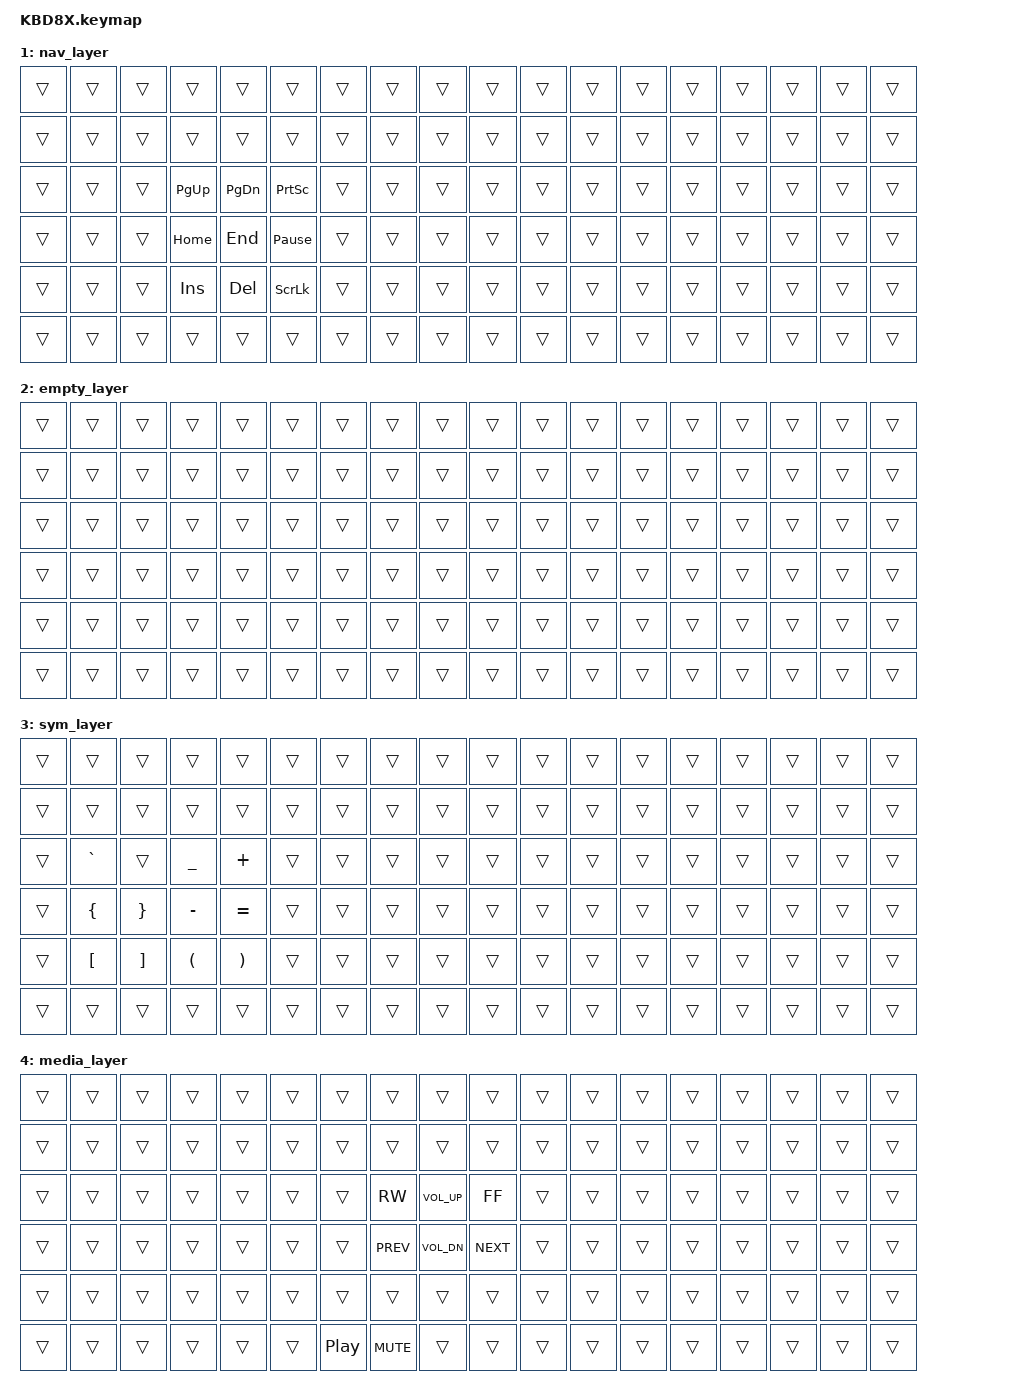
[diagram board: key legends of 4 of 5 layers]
/*
 * Copyright (c) 2020 The ZMK Contributors
 * test
 * SPDX-License-Identifier: MIT
 */

#include <behaviors.dtsi>
#include <dt-bindings/zmk/keys.h>

#define BASE 0
#define NAV 1
#define EMPTY 2
#define SYM 3
#define MEDIA 4

/ {

    keymap {
        compatible = "zmk,keymap";

        base {

// --------- Default QWERTY Layout ---------
// Layer 0 BASE
// --------------------------------------------------------------------------------------------------------------
// | ESC |     | F1  | F2  | F3  | F4  | F5  | F6  | F7  | F8  |     | F9  | F10 | F11 | F12 |PrtSc|Scrll| Pause|
// --------------------------------------------------------------------------------------------------------------
// |  ~  |  1  |  2  |  3  |  4  |  5  |  6  |  7  |  8  |  9  |  0  |  ÷  |  ×  |  -  | Bspc| Ins | Home| PgUp |
// --------------------------------------------------------------------------------------------------------------
// | TAB |  Q  |  W  |  E  |  R  |  T  |  Y  |  U  |  I  |  O  |  P  | N7  | N8  | N9  |  \  | Del | End | PgDn |
// --------------------------------------------------------------------------------------------------------------
// | Fn1 |  A  |  S  |  D  |  F  |  G  |  H  |  J  |  K  |  L  |  ;  | N4  | N5  | N6  |  +  |                  |
// --------------------------------------------------------------------------------------------------------------
// |LSHFT|  Z  |  X  |  C  |  V  |  B  |  N  |  M  |  ,  |  .  |  /  | N1  | N2  | N3  |Enter|     | Up  |      |
// --------------------------------------------------------------------------------------------------------------
// | LCTL| LGUI| LALT| Fn2 | Fn3 | Spc | Bspc|  '  | Fn4 | RALT| RGUI| N0  | N00 | N.  |RCTRL| Left| Down| Right|
// --------------------------------------------------------------------------------------------------------------


            bindings = <
                &kp ESC    &trans    &kp F1    &kp F2     &kp F3     &kp F4     &kp F5    &kp F6   &kp F7     &kp F8              &kp F9        &kp F10          &kp F11       &kp F12      &kp PSCRN  &kp SLCK  &kp PAUSE_BREAK
                &kp TILDE  &kp N1    &kp N2    &kp N3     &kp N4     &kp N5     &kp N6    &kp N7   &kp N8     &kp N9    &kp N0    &kp KP_SLASH  &kp KP_MULTIPLY  &kp KP_MINUS  &kp BSPC     &kp INS    &kp HOME  &kp PG_UP
                &kp TAB    &kp Q     &kp W     &kp E      &kp R      &kp T      &kp Y     &kp U    &kp I      &kp O     &kp P     &kp KP_N7     &kp KP_N8        &kp KP_N9     &kp BSLH     &kp DEL    &kp END   &kp PG_DN
                &kp LBKT   &kp A     &kp S     &kp D      &kp F      &kp G      &kp H     &kp J    &kp K      &kp L     &kp SEMI  &kp KP_N4     &kp KP_N5        &kp KP_N6     &kp KP_PLUS  &trans     &trans    &trans
                &kp LSHFT  &kp Z     &kp X     &kp C      &kp V      &kp B      &kp N     &kp M    &kp COMMA  &kp DOT   &kp FSLH  &kp KP_N1     &kp KP_N2        &kp KP_N3     &kp ENTER    &trans     &kp UP    &trans
                &kp LCTRL  &kp LGUI  &kp LALT  &kp RBKT   &kp PLUS   &kp SPACE  &kp BSPC  &kp SQT  &kp EQUAL  &kp RALT  &kp RGUI  &kp KP_N0     &kp KP_N0        &kp KP_DOT    &kp RCTRL    &kp LEFT   &kp DOWN  &kp RIGHT
            >;
            sensor-bindings = <&inc_dec_kp C_VOL_DN C_VOL_UP>;
        };

        nav_layer {
// Layer 1 FUNC1
// --------------------------------------------------------------------------------------------------------------
// |     |     |     |     |     |     |     |     |     |     |     |     |     |     |     |     |     |      |
// --------------------------------------------------------------------------------------------------------------
// |     |     |     |     |     |     |     |     |     |     |     |     |     |     |     |     |     |      |
// --------------------------------------------------------------------------------------------------------------
// |     |     |     | PgUp| PgDn| Pscr|     |     |     |     |     |     |     |     |     |     |     |      |
// --------------------------------------------------------------------------------------------------------------
// | Fn1 |     |     | Home| End |Pause|     |     |     |     |     |     |     |     |     |     |     |      |
// --------------------------------------------------------------------------------------------------------------
// |     |     |     | Ins | Del | Slck|     |     |     |     |     |     |     |     |     |     |     |      |
// --------------------------------------------------------------------------------------------------------------
// |     |     |     |     |     |     |     |     |     |     |     |     |     |     |     |     |     |      |
// --------------------------------------------------------------------------------------------------------------
            bindings = <
                &trans  &trans     &trans    &trans     &trans     &trans           &trans  &trans  &trans  &trans  &trans  &trans  &trans  &trans  &trans  &trans  &trans  &trans
                &trans  &trans     &trans    &trans     &trans     &trans           &trans  &trans  &trans  &trans  &trans  &trans  &trans  &trans  &trans  &trans  &trans  &trans
                &trans  &trans     &trans    &kp PG_UP  &kp PG_DN  &kp PSCRN        &trans  &trans  &trans  &trans  &trans  &trans  &trans  &trans  &trans  &trans  &trans  &trans
                &trans  &trans     &trans    &kp HOME   &kp END    &kp PAUSE_BREAK  &trans  &trans  &trans  &trans  &trans  &trans  &trans  &trans  &trans  &trans  &trans  &trans
                &trans  &trans     &trans    &kp INS    &kp DEL    &kp SLCK         &trans  &trans  &trans  &trans  &trans  &trans  &trans  &trans  &trans  &trans  &trans  &trans
                &trans  &trans     &trans    &trans     &trans     &trans           &trans  &trans  &trans  &trans  &trans  &trans  &trans  &trans  &trans  &trans  &trans  &trans
            >;
        };

        empty_layer {
// Layer 2 FUNC2
// --------------------------------------------------------------------------------------------------------------
// |     |     |     |     |     |     |     |     |     |     |     |     |     |     |     |     |     |      |
// --------------------------------------------------------------------------------------------------------------
// |     |     |     |     |     |     |     |     |     |     |     |     |     |     |     |     |     |      |
// --------------------------------------------------------------------------------------------------------------
// |     |     |     |     |     |     |     |     |     |     |     |     |     |     |     |     |     |      |
// --------------------------------------------------------------------------------------------------------------
// |     |     |     |     |     |     |     |     |     |     |     |     |     |     |     |     |     |      |
// --------------------------------------------------------------------------------------------------------------
// |     |     |     |     |     |     |     |     |     |     |     |     |     |     |     |     |     |      |
// --------------------------------------------------------------------------------------------------------------
// |     |     |     | Fn2 |     |     |     |     |     |     |     |     |     |     |     |     |     |      |
// --------------------------------------------------------------------------------------------------------------
            bindings = <
                &trans  &trans  &trans  &trans  &trans  &trans  &trans  &trans  &trans  &trans  &trans  &trans  &trans  &trans  &trans  &trans  &trans  &trans
                &trans  &trans  &trans  &trans  &trans  &trans  &trans  &trans  &trans  &trans  &trans  &trans  &trans  &trans  &trans  &trans  &trans  &trans
                &trans  &trans  &trans  &trans  &trans  &trans  &trans  &trans  &trans  &trans  &trans  &trans  &trans  &trans  &trans  &trans  &trans  &trans
                &trans  &trans  &trans  &trans  &trans  &trans  &trans  &trans  &trans  &trans  &trans  &trans  &trans  &trans  &trans  &trans  &trans  &trans
                &trans  &trans  &trans  &trans  &trans  &trans  &trans  &trans  &trans  &trans  &trans  &trans  &trans  &trans  &trans  &trans  &trans  &trans
                &trans  &trans  &trans  &trans  &trans  &trans  &trans  &trans  &trans  &trans  &trans  &trans  &trans  &trans  &trans  &trans  &trans  &trans
            >;
        };

        sym_layer {
// Layer 3 FUNC3
// --------------------------------------------------------------------------------------------------------------
// |     |     |     |     |     |     |     |     |     |     |     |     |     |     |     |     |     |      |
// --------------------------------------------------------------------------------------------------------------
// |     |     |     |     |     |     |     |     |     |     |     |     |     |     |     |     |     |      |
// --------------------------------------------------------------------------------------------------------------
// |     |  `  |     |  _  |  +  |     |     |     |     |     |     |     |     |     |     |     |     |      |
// --------------------------------------------------------------------------------------------------------------
// |     |  {  |  }  |  -  |  =  |     |     |     |     |     |     |     |     |     |     |     |     |      |
// --------------------------------------------------------------------------------------------------------------
// |     |  [  |  ]  |  (  |  )  |     |     |     |     |     |     |     |     |     |     |     |     |      |
// --------------------------------------------------------------------------------------------------------------
// |     |     |     |     | Fn3 |     |     |     |     |     |     |     |     |     |     |     |     |      |
// --------------------------------------------------------------------------------------------------------------
            bindings = <
                &trans  &trans     &trans    &trans     &trans     &trans   &trans  &trans  &trans  &trans  &trans  &trans  &trans  &trans  &trans  &trans  &trans  &trans
                &trans  &trans     &trans    &trans     &trans     &trans   &trans  &trans  &trans  &trans  &trans  &trans  &trans  &trans  &trans  &trans  &trans  &trans
                &trans  &kp GRAVE  &trans    &kp UNDER  &kp PLUS   &trans   &trans  &trans  &trans  &trans  &trans  &trans  &trans  &trans  &trans  &trans  &trans  &trans
                &trans  &kp LBRC   &kp RBRC  &kp MINUS  &kp EQUAL  &trans   &trans  &trans  &trans  &trans  &trans  &trans  &trans  &trans  &trans  &trans  &trans  &trans
                &trans  &kp LBKT   &kp RBKT  &kp LPAR   &kp RPAR   &trans   &trans  &trans  &trans  &trans  &trans  &trans  &trans  &trans  &trans  &trans  &trans  &trans
                &trans  &trans     &trans    &trans     &trans     &trans   &trans  &trans  &trans  &trans  &trans  &trans  &trans  &trans  &trans  &trans  &trans  &trans
            >;
        };

        media_layer {
// Layer 4 FUNC4
// --------------------------------------------------------------------------------------------------------------
// |     |     |     |     |     |     |     |     |     |     |     |     |     |     |     |     |     |      |
// --------------------------------------------------------------------------------------------------------------
// |     |     |     |     |     |     |     |     |     |     |     |     |     |     |     |     |     |      |
// --------------------------------------------------------------------------------------------------------------
// |     |     |     |     |     |     |     |Rewnd| Vol+|FstFr|     |     |     |     |     |     |     |      |
// --------------------------------------------------------------------------------------------------------------
// |     |     |     |     |     |     |     | Prev| Vol-| Next|     |     |     |     |     |     |     |      |
// --------------------------------------------------------------------------------------------------------------
// |     |     |     |     |     |     |     |     |     |     |     |     |     |     |     |     |     |      |
// --------------------------------------------------------------------------------------------------------------
// |     |     |     |     |     |     | Play| Mute|     |     |     |     |     |     |     |     |      |     |
// --------------------------------------------------------------------------------------------------------------
            bindings = <
                &trans  &trans  &trans  &trans  &trans  &trans  &trans    &trans      &trans        &trans       &trans  &trans  &trans  &trans  &trans  &trans  &trans  &trans
                &trans  &trans  &trans  &trans  &trans  &trans  &trans    &trans      &trans        &trans       &trans  &trans  &trans  &trans  &trans  &trans  &trans  &trans
                &trans  &trans  &trans  &trans  &trans  &trans  &trans    &kp C_RW    &kp C_VOL_UP  &kp C_FF     &trans  &trans  &trans  &trans  &trans  &trans  &trans  &trans
                &trans  &trans  &trans  &trans  &trans  &trans  &trans    &kp C_PREV  &kp C_VOL_DN  &kp C_NEXT   &trans  &trans  &trans  &trans  &trans  &trans  &trans  &trans
                &trans  &trans  &trans  &trans  &trans  &trans  &trans    &trans      &trans        &trans       &trans  &trans  &trans  &trans  &trans  &trans  &trans  &trans
                &trans  &trans  &trans  &trans  &trans  &trans  &kp C_PP  &kp C_MUTE  &trans        &trans       &trans  &trans  &trans  &trans  &trans  &trans  &trans  &trans
            >;
        };
    };
};
